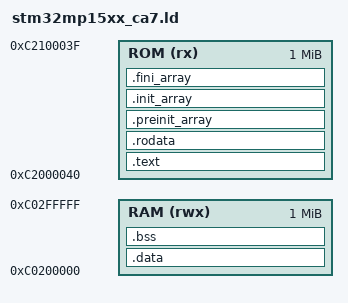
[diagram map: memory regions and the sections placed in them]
OUTPUT_FORMAT("elf32-littlearm", "elf32-littlearm", "elf32-littlearm")
OUTPUT_ARCH(arm)
ENTRY(_Reset)

MEMORY
{
    ROM (rx) : ORIGIN = 0xC2000040, LENGTH = 1M
    RAM (rwx): ORIGIN = 0xC0200000, LENGTH = 1M
}

SECTIONS
{
    .text : {
        *(.vector_table)
        *(.text*)
					/* Todo: check if we need the next 5 lines */
		*(.glue_7)         /* glue arm to thumb code */
		*(.glue_7t)        /* glue thumb to arm code */
		*(.eh_frame)
		KEEP (*(.init))
		KEEP (*(.fini))

        . = ALIGN(8);
     } > ROM

	.rodata :
	{
		. = ALIGN(8);
		*(.rodata)         /* .rodata sections (constants, strings, etc.) */
		*(.rodata*)        /* .rodata* sections (constants, strings, etc.) */
		. = ALIGN(8);
	} > ROM


	.preinit_array :
	{
		. = ALIGN(8);
		PROVIDE_HIDDEN (__preinit_array_start = .);
		KEEP (*(.preinit_array*))
		PROVIDE_HIDDEN (__preinit_array_end = .);
		. = ALIGN(8);
	} > ROM

	.init_array :
	{
		. = ALIGN(8);
		PROVIDE_HIDDEN (__init_array_start = .);
		KEEP (*(SORT(.init_array.*)))
		KEEP (*(.init_array*))
		PROVIDE_HIDDEN (__init_array_end = .);
		. = ALIGN(8);
	} > ROM

	.fini_array :
	{
		. = ALIGN(8);
		PROVIDE_HIDDEN (__fini_array_start = .);
		KEEP (*(SORT(.fini_array.*)))
		KEEP (*(.fini_array*))
		PROVIDE_HIDDEN (__fini_array_end = .);
		. = ALIGN(8);
	} > ROM


    _text_end = .;

    /* .data : AT(ADDR(.text) + SIZEOF(.text)) */
    .data : AT(_text_end)
    {
        . = ALIGN(8);
        _data_start = .;
        *(.data)
        *(.data*)
        . = ALIGN(8);
        _data_end = .;
    } > RAM

    .bss : {
        _bss_start = .;
        *(.bss)
        . = ALIGN(8);
        _bss_end = .;
    } > RAM

    _fiq_stack_start = ADDR(.bss) + SIZEOF(.bss);
    _fiq_stack_end = _fiq_stack_start + 0x1000; /* 64 KB */

    _irq_stack_start = _fiq_stack_end;
    _irq_stack_end = _irq_stack_start + 0x1000; /* 64 KB */

    _stack_start = _irq_stack_end;
    _stack_end = _stack_start + 0x1000; /* 64 KB */

    _irq_stack_size = _irq_stack_end - _irq_stack_start;
    _fiq_stack_size = _fiq_stack_end - _fiq_stack_start;

  /* Remove information from the compiler libraries */
  /DISCARD/ :
  {
    libc.a ( * )
    libm.a ( * )
    libgcc.a ( * )
  }
}
